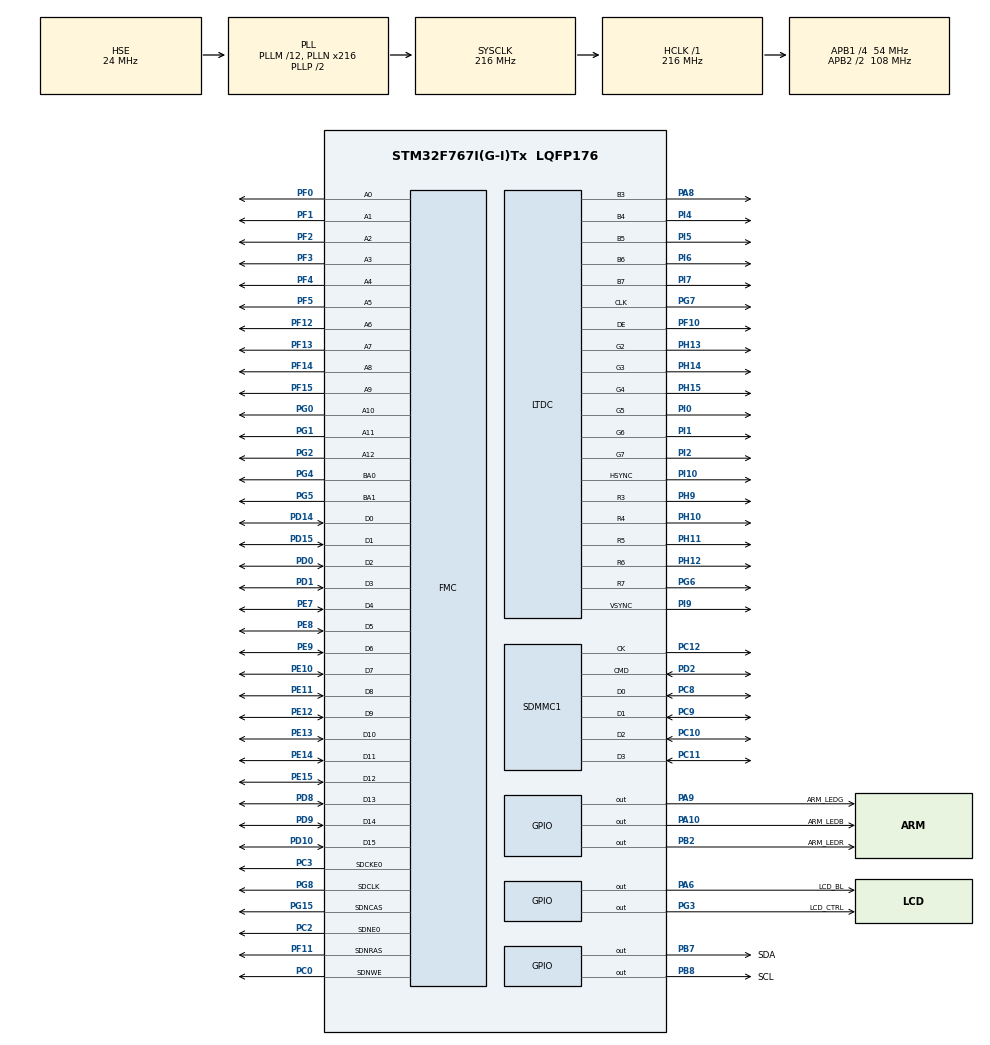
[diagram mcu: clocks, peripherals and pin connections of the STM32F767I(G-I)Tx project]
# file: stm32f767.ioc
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Dma.MEMTOMEM.0.Direction=DMA_MEMORY_TO_MEMORY
Dma.MEMTOMEM.0.FIFOMode=DMA_FIFOMODE_ENABLE
Dma.MEMTOMEM.0.FIFOThreshold=DMA_FIFO_THRESHOLD_FULL
Dma.MEMTOMEM.0.Instance=DMA2_Stream0
Dma.MEMTOMEM.0.MemBurst=DMA_MBURST_SINGLE
Dma.MEMTOMEM.0.MemDataAlignment=DMA_MDATAALIGN_BYTE
Dma.MEMTOMEM.0.MemInc=DMA_MINC_ENABLE
Dma.MEMTOMEM.0.Mode=DMA_NORMAL
Dma.MEMTOMEM.0.PeriphBurst=DMA_PBURST_SINGLE
Dma.MEMTOMEM.0.PeriphDataAlignment=DMA_PDATAALIGN_BYTE
Dma.MEMTOMEM.0.PeriphInc=DMA_PINC_ENABLE
Dma.MEMTOMEM.0.Priority=DMA_PRIORITY_LOW
Dma.Request0=MEMTOMEM
FATFS._CODE_PAGE=936
FATFS._USE_FASTSEEK=0
FATFS._USE_MKFS=0
FMC.CASLatency1=FMC_SDRAM_CAS_LATENCY_3
FMC.ColumnBitsNumber1=FMC_SDRAM_COLUMN_BITS_NUM_9
FMC.ExitSelfRefreshDelay1=7
FMC.LoadToActiveDelay1=2
FMC.RCDDelay1=2
FMC.RPDelay1=2
FMC.RPDelay2=2
FMC.ReadBurst1=FMC_SDRAM_RBURST_ENABLE
FMC.ReadBurst2=FMC_SDRAM_RBURST_ENABLE
FMC.ReadPipeDelay1=FMC_SDRAM_RPIPE_DELAY_1
FMC.ReadPipeDelay2=FMC_SDRAM_RPIPE_DELAY_1
FMC.RowCycleDelay1=7
FMC.RowCycleDelay2=7
FMC.SDClockPeriod1=FMC_SDRAM_CLOCK_PERIOD_2
FMC.SDClockPeriod2=FMC_SDRAM_CLOCK_PERIOD_2
FMC.SelfRefreshTime1=4
FMC.WriteRecoveryTime1=4
LTDC.ActiveH=272
LTDC.ActiveW=480
LTDC.Blue=255
LTDC.Blue_L0=255
LTDC.FBStartAdress_L1=272
LTDC.Green=255
LTDC.Green_L0=255
LTDC.HBP=20
LTDC.HFP=24
LTDC.HSync=1
LTDC.ImageWidth_L0=480
LTDC.Red=255
LTDC.Red_L0=255
LTDC.VBP=9
LTDC.VFP=6
LTDC.VSync=1
LTDC.WindowX1_L0=480
LTDC.WindowY1_L0=272
Mcu.Family=STM32F7
Mcu.Name=STM32F767I(G-I)Tx
Mcu.Package=LQFP176
NVIC.PriorityGroup=NVIC_PRIORITYGROUP_4
PA10.GPIO_Label=ARM_LEDB
PA10.GPIO_Speed=GPIO_SPEED_FREQ_VERY_HIGH
PA10.PinState=GPIO_PIN_SET
PA10.Signal=GPIO_Output
PA13.Mode=Serial_Wire
PA13.Signal=SYS_JTMS-SWDIO
PA14.Mode=Serial_Wire
PA14.Signal=SYS_JTCK-SWCLK
PA6.GPIO_Label=LCD_BL
PA6.GPIO_Speed=GPIO_SPEED_FREQ_VERY_HIGH
PA6.PinState=GPIO_PIN_SET
PA6.Signal=GPIO_Output
PA8.GPIO_Speed=GPIO_SPEED_FREQ_VERY_HIGH
PA8.Mode=RGB565
PA8.Signal=LTDC_B3
PA9.GPIO_Label=ARM_LEDG
PA9.GPIO_Speed=GPIO_SPEED_FREQ_VERY_HIGH
PA9.PinState=GPIO_PIN_SET
PA9.Signal=GPIO_Output
PB2.GPIO_Label=ARM_LEDR
PB2.GPIO_Speed=GPIO_SPEED_FREQ_VERY_HIGH
PB2.PinState=GPIO_PIN_SET
PB2.Signal=GPIO_Output
PB7.GPIO_Label=SDA
PB7.GPIO_Speed=GPIO_SPEED_FREQ_VERY_HIGH
PB7.PinState=GPIO_PIN_SET
PB7.Signal=GPIO_Output
PB8.GPIO_Label=SCL
PB8.GPIO_Speed=GPIO_SPEED_FREQ_VERY_HIGH
PB8.PinState=GPIO_PIN_SET
PB8.Signal=GPIO_Output
PC0.GPIO_PuPd=GPIO_NOPULL
PC0.Signal=FMC_SDNWE
PC10.Mode=SD_4_bits_Wide_bus
PC10.Signal=SDMMC1_D2
PC11.Mode=SD_4_bits_Wide_bus
PC11.Signal=SDMMC1_D3
PC12.Mode=SD_4_bits_Wide_bus
PC12.Signal=SDMMC1_CK
PC2.Mode=SdramChipSelect1_1
PC2.Signal=FMC_SDNE0
PC3.Mode=SdramChipSelect1_1
PC3.Signal=FMC_SDCKE0
PC8.Mode=SD_4_bits_Wide_bus
PC8.Signal=SDMMC1_D0
PC9.Mode=SD_4_bits_Wide_bus
PC9.Signal=SDMMC1_D1
PD0.Signal=FMC_D2_DA2
PD1.Signal=FMC_D3_DA3
PD10.Signal=FMC_D15_DA15
PD14.Signal=FMC_D0_DA0
PD15.Signal=FMC_D1_DA1
PD2.Mode=SD_4_bits_Wide_bus
PD2.Signal=SDMMC1_CMD
PD8.Signal=FMC_D13_DA13
PD9.Signal=FMC_D14_DA14
PE10.Signal=FMC_D7_DA7
PE11.Signal=FMC_D8_DA8
PE12.Signal=FMC_D9_DA9
PE13.Signal=FMC_D10_DA10
PE14.Signal=FMC_D11_DA11
PE15.Signal=FMC_D12_DA12
PE7.Signal=FMC_D4_DA4
PE8.Signal=FMC_D5_DA5
PE9.Signal=FMC_D6_DA6
PF0.Signal=FMC_A0
PF1.Signal=FMC_A1
PF10.GPIO_Speed=GPIO_SPEED_FREQ_VERY_HIGH
PF10.Mode=RGB565
PF10.Signal=LTDC_DE
PF11.Signal=FMC_SDNRAS
PF12.Signal=FMC_A6
PF13.Signal=FMC_A7
PF14.Signal=FMC_A8
PF15.Signal=FMC_A9
PF2.Signal=FMC_A2
PF3.Signal=FMC_A3
PF4.Signal=FMC_A4
PF5.Signal=FMC_A5
PG0.Signal=FMC_A10
PG1.Signal=FMC_A11
PG15.Signal=FMC_SDNCAS
PG2.Signal=FMC_A12
PG3.GPIO_Label=LCD_CTRL
PG3.GPIO_Speed=GPIO_SPEED_FREQ_VERY_HIGH
PG3.PinState=GPIO_PIN_SET
PG3.Signal=GPIO_Output
PG4.Signal=FMC_A14_BA0
PG5.Signal=FMC_A15_BA1
PG6.GPIO_Speed=GPIO_SPEED_FREQ_VERY_HIGH
PG6.Mode=RGB565
PG6.Signal=LTDC_R7
PG7.GPIO_Speed=GPIO_SPEED_FREQ_VERY_HIGH
PG7.Mode=RGB565
PG7.Signal=LTDC_CLK
PG8.Signal=FMC_SDCLK
PH0/OSC_IN.Mode=HSE-External-Oscillator
PH0/OSC_IN.Signal=RCC_OSC_IN
PH1/OSC_OUT.Mode=HSE-External-Oscillator
PH1/OSC_OUT.Signal=RCC_OSC_OUT
PH10.GPIO_Speed=GPIO_SPEED_FREQ_VERY_HIGH
PH10.Mode=RGB565
PH10.Signal=LTDC_R4
PH11.GPIO_Speed=GPIO_SPEED_FREQ_VERY_HIGH
PH11.Mode=RGB565
PH11.Signal=LTDC_R5
PH12.GPIO_Speed=GPIO_SPEED_FREQ_VERY_HIGH
PH12.Mode=RGB565
PH12.Signal=LTDC_R6
PH13.GPIO_Speed=GPIO_SPEED_FREQ_VERY_HIGH
PH13.Mode=RGB565
PH13.Signal=LTDC_G2
PH14.GPIO_Speed=GPIO_SPEED_FREQ_VERY_HIGH
PH14.Mode=RGB565
PH14.Signal=LTDC_G3
PH15.GPIO_Speed=GPIO_SPEED_FREQ_VERY_HIGH
PH15.Mode=RGB565
PH15.Signal=LTDC_G4
PH9.GPIO_Speed=GPIO_SPEED_FREQ_VERY_HIGH
PH9.Mode=RGB565
PH9.Signal=LTDC_R3
PI0.GPIO_Speed=GPIO_SPEED_FREQ_VERY_HIGH
PI0.Mode=RGB565
PI0.Signal=LTDC_G5
PI1.GPIO_Speed=GPIO_SPEED_FREQ_VERY_HIGH
PI1.Mode=RGB565
PI1.Signal=LTDC_G6
PI10.GPIO_Speed=GPIO_SPEED_FREQ_VERY_HIGH
PI10.Mode=RGB565
PI10.Signal=LTDC_HSYNC
PI2.GPIO_Speed=GPIO_SPEED_FREQ_VERY_HIGH
PI2.Mode=RGB565
PI2.Signal=LTDC_G7
PI4.GPIO_Speed=GPIO_SPEED_FREQ_VERY_HIGH
PI4.Mode=RGB565
PI4.Signal=LTDC_B4
PI5.GPIO_Speed=GPIO_SPEED_FREQ_VERY_HIGH
PI5.Mode=RGB565
PI5.Signal=LTDC_B5
PI6.GPIO_Speed=GPIO_SPEED_FREQ_VERY_HIGH
PI6.Mode=RGB565
PI6.Signal=LTDC_B6
PI7.GPIO_Speed=GPIO_SPEED_FREQ_VERY_HIGH
PI7.Mode=RGB565
PI7.Signal=LTDC_B7
PI9.GPIO_Speed=GPIO_SPEED_FREQ_VERY_HIGH
PI9.Mode=RGB565
PI9.Signal=LTDC_VSYNC
ProjectManager.HeapSize=0x800
ProjectManager.StackSize=0x2000
ProjectManager.TargetToolchain=MDK-ARM V5.27
RCC.AHBFreq_Value=216000000
RCC.APB1CLKDivider=RCC_HCLK_DIV4
RCC.APB1Freq_Value=54000000
RCC.APB1TimFreq_Value=108000000
RCC.APB2CLKDivider=RCC_HCLK_DIV2
RCC.APB2Freq_Value=108000000
RCC.APB2TimFreq_Value=216000000
RCC.CortexFreq_Value=216000000
RCC.HCLKFreq_Value=216000000
RCC.HSE_VALUE=24000000
RCC.HSI_VALUE=16000000
RCC.LSE_VALUE=32768
RCC.PLLM=12
RCC.PLLN=216
RCC.PLLQ=9
RCC.PLLSAIN=144
RCC.PLLSAIRDiv=RCC_PLLSAIDIVR_16
RCC.PLLSourceVirtual=RCC_PLLSOURCE_HSE
RCC.SDMMCClockSelection=RCC_SDMMC1CLKSOURCE_CLK48
RCC.SYSCLKFreq_VALUE=216000000
RCC.SYSCLKSource=RCC_SYSCLKSOURCE_PLLCLK
RCC.USBFreq_Value=48000000
RCC.VCOOutputFreq_Value=432000000
SDMMC1.ClockDiv=10
SH.FMC_A0.0=FMC_A0,13b-sda1
SH.FMC_A1.0=FMC_A1,13b-sda1
SH.FMC_A10.0=FMC_A10,13b-sda1
SH.FMC_A11.0=FMC_A11,13b-sda1
SH.FMC_A12.0=FMC_A12,13b-sda1
SH.FMC_A14_BA0.0=FMC_BA0,FourSdramBanks1
SH.FMC_A15_BA1.0=FMC_BA1,FourSdramBanks1
SH.FMC_A2.0=FMC_A2,13b-sda1
SH.FMC_A3.0=FMC_A3,13b-sda1
SH.FMC_A4.0=FMC_A4,13b-sda1
SH.FMC_A5.0=FMC_A5,13b-sda1
SH.FMC_A6.0=FMC_A6,13b-sda1
SH.FMC_A7.0=FMC_A7,13b-sda1
SH.FMC_A8.0=FMC_A8,13b-sda1
SH.FMC_A9.0=FMC_A9,13b-sda1
SH.FMC_D0_DA0.0=FMC_D0,sd-16b-d1
SH.FMC_D10_DA10.0=FMC_D10,sd-16b-d1
SH.FMC_D11_DA11.0=FMC_D11,sd-16b-d1
SH.FMC_D12_DA12.0=FMC_D12,sd-16b-d1
SH.FMC_D13_DA13.0=FMC_D13,sd-16b-d1
SH.FMC_D14_DA14.0=FMC_D14,sd-16b-d1
SH.FMC_D15_DA15.0=FMC_D15,sd-16b-d1
SH.FMC_D1_DA1.0=FMC_D1,sd-16b-d1
SH.FMC_D2_DA2.0=FMC_D2,sd-16b-d1
SH.FMC_D3_DA3.0=FMC_D3,sd-16b-d1
SH.FMC_D4_DA4.0=FMC_D4,sd-16b-d1
SH.FMC_D5_DA5.0=FMC_D5,sd-16b-d1
SH.FMC_D6_DA6.0=FMC_D6,sd-16b-d1
SH.FMC_D7_DA7.0=FMC_D7,sd-16b-d1
SH.FMC_D8_DA8.0=FMC_D8,sd-16b-d1
SH.FMC_D9_DA9.0=FMC_D9,sd-16b-d1
SH.FMC_SDCLK.0=FMC_SDCLK,13b-sda1
SH.FMC_SDNCAS.0=FMC_SDNCAS,13b-sda1
SH.FMC_SDNRAS.0=FMC_SDNRAS,13b-sda1
SH.FMC_SDNWE.0=FMC_SDNWE,13b-sda1
VP_CRC_VS_CRC.Mode=CRC_Activate
VP_FATFS_VS_SDIO.Mode=SDIO
board=custom

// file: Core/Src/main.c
/* USER CODE BEGIN Header */
/**
  ******************************************************************************
  * @file           : main.c
  * @brief          : Main program body
  ******************************************************************************
  * @attention
  *
  * <h2><center>&copy; Copyright (c) 2020 STMicroelectronics.
  * All rights reserved.</center></h2>
  *
  * This software component is licensed by ST under BSD 3-Clause license,
  * the "License"; You may not use this file except in compliance with the
  * License. You may obtain a copy of the License at:
  *                        opensource.org/licenses/BSD-3-Clause
  *
  ******************************************************************************
  */
/* USER CODE END Header */
#include "main.h"
#include "crc.h"
#include "dma.h"
#include "fatfs.h"
#include "ltdc.h"
#include "sdmmc.h"
#include "gpio.h"
#include "fmc.h"

/* USER CODE BEGIN Includes */
#include "GUI.h"
#include "gt911.h"
#include "ns2009.h"
#include "frame.h"
#include "lcd.h"
#include "power_on.h"
#include "stm32f769i_discovery_sdram.h"
/* USER CODE END Includes */

/* USER CODE BEGIN PV */
FATFS fatfs;
int touch_type;
/* USER CODE END PV */

void SystemClock_Config(void);

int main(void)
{
  /* USER CODE BEGIN 1 */
	FRESULT res;
  /* USER CODE END 1 */

  /* MCU Configuration--------------------------------------------------------*/

  /* Reset of all peripherals, Initializes the Flash interface and the Systick. */
  HAL_Init();

  /* Configure the system clock */
  SystemClock_Config();

  /* USER CODE BEGIN SysInit */
	BSP_SDRAM_Init();
  /* USER CODE END SysInit */

  /* Initialize all configured peripherals */
  MX_GPIO_Init();
  MX_DMA_Init();
  MX_FMC_Init();
  MX_LTDC_Init();
  MX_SDMMC1_SD_Init();
  MX_FATFS_Init();
  MX_CRC_Init();
  /* USER CODE BEGIN 2 */

	MX_FATFS_Init();
	lcd.initialize();

	LED_BLUE_ON;  //蓝灯亮
	LCD_CTRL_ON;  //液晶屏使能
	LCD_BL_ON;    //背光亮

	GUI_Init();                  //STemWin初始化
	GUI_SetBkColor(GUI_BLACK);
	GUI_Clear();
	//判断是否为电容触摸
	touch_type = gt911.initialize();
	if(touch_type != TOUCH_CAP){
		touch_type = TOUCH_RES;
	}

	res = f_mount(&fatfs,"0:",1);
	if(res != RES_OK){
		GUI_SetColor(GUI_RED);
		GUI_SetFont(&GUI_FontFixedsys16);
		GUI_DispStringHCenterAt("f_mount Error!",480/2,272/2);
		while(1){
		}
	}
	GUI_SetColor(GUI_WHITE);

	if(touch_type == TOUCH_RES){
		power_on.check_touch();
	}

	GUI_Clear();
	GUI_CURSOR_Show();
	frame.process();                  //界面处理

  /* USER CODE END 2 */

  /* Infinite loop */
  while (1)
  {

  }
}

void SystemClock_Config(void)
{
  RCC_OscInitTypeDef RCC_OscInitStruct = {0};
  RCC_ClkInitTypeDef RCC_ClkInitStruct = {0};
  RCC_PeriphCLKInitTypeDef PeriphClkInitStruct = {0};

  /** Configure the main internal regulator output voltage
  */
  __HAL_RCC_PWR_CLK_ENABLE();
  __HAL_PWR_VOLTAGESCALING_CONFIG(PWR_REGULATOR_VOLTAGE_SCALE1);
  /** Initializes the RCC Oscillators according to the specified parameters
  * in the RCC_OscInitTypeDef structure.
  */
  RCC_OscInitStruct.OscillatorType = RCC_OSCILLATORTYPE_HSE;
  RCC_OscInitStruct.HSEState = RCC_HSE_ON;
  RCC_OscInitStruct.PLL.PLLState = RCC_PLL_ON;
  RCC_OscInitStruct.PLL.PLLSource = RCC_PLLSOURCE_HSE;
  RCC_OscInitStruct.PLL.PLLM = 12;
  RCC_OscInitStruct.PLL.PLLN = 216;
  RCC_OscInitStruct.PLL.PLLP = RCC_PLLP_DIV2;
  RCC_OscInitStruct.PLL.PLLQ = 9;
  if (HAL_RCC_OscConfig(&RCC_OscInitStruct) != HAL_OK)
  {
    Error_Handler();
  }
  /** Activate the Over-Drive mode
  */
  if (HAL_PWREx_EnableOverDrive() != HAL_OK)
  {
    Error_Handler();
  }
  /** Initializes the CPU, AHB and APB buses clocks
  */
  RCC_ClkInitStruct.ClockType = RCC_CLOCKTYPE_HCLK|RCC_CLOCKTYPE_SYSCLK
                              |RCC_CLOCKTYPE_PCLK1|RCC_CLOCKTYPE_PCLK2;
  RCC_ClkInitStruct.SYSCLKSource = RCC_SYSCLKSOURCE_PLLCLK;
  RCC_ClkInitStruct.AHBCLKDivider = RCC_SYSCLK_DIV1;
  RCC_ClkInitStruct.APB1CLKDivider = RCC_HCLK_DIV4;
  RCC_ClkInitStruct.APB2CLKDivider = RCC_HCLK_DIV2;

  if (HAL_RCC_ClockConfig(&RCC_ClkInitStruct, FLASH_LATENCY_7) != HAL_OK)
  {
    Error_Handler();
  }
  PeriphClkInitStruct.PeriphClockSelection = RCC_PERIPHCLK_LTDC|RCC_PERIPHCLK_SDMMC1
                              |RCC_PERIPHCLK_CLK48;
  PeriphClkInitStruct.PLLSAI.PLLSAIN = 144;
  PeriphClkInitStruct.PLLSAI.PLLSAIR = 2;
  PeriphClkInitStruct.PLLSAI.PLLSAIQ = 2;
  PeriphClkInitStruct.PLLSAI.PLLSAIP = RCC_PLLSAIP_DIV2;
  PeriphClkInitStruct.PLLSAIDivQ = 1;
  PeriphClkInitStruct.PLLSAIDivR = RCC_PLLSAIDIVR_16;
  PeriphClkInitStruct.Clk48ClockSelection = RCC_CLK48SOURCE_PLL;
  PeriphClkInitStruct.Sdmmc1ClockSelection = RCC_SDMMC1CLKSOURCE_CLK48;
  if (HAL_RCCEx_PeriphCLKConfig(&PeriphClkInitStruct) != HAL_OK)
  {
    Error_Handler();
  }
}

void Error_Handler(void)
{
  __disable_irq();
  while (1)
  {
  }
}

/************************ (C) COPYRIGHT STMicroelectronics *****END OF FILE****/
